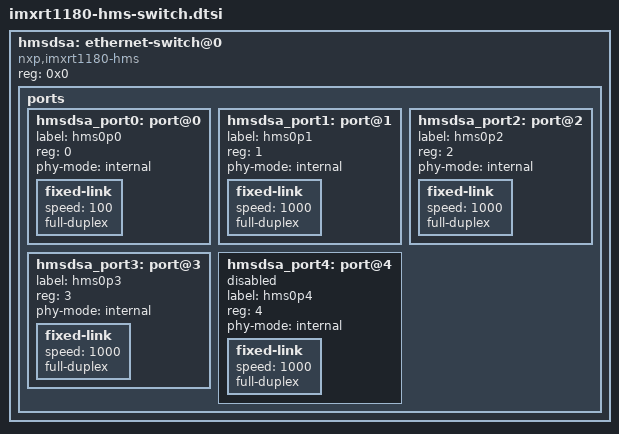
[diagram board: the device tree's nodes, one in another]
// SPDX-License-Identifier: (GPL-2.0+ OR MIT)
/*
 * Copyright 2026 NXP
 */

hmsdsa: ethernet-switch@0 {
	reg = <0x0>;
	#address-cells = <1>;
	#size-cells = <0>;
	compatible = "nxp,imxrt1180-hms";

	ports {
		#address-cells = <1>;
		#size-cells = <0>;

		hmsdsa_port0: port@0 {
			label = "hms0p0";
			reg = <0>;
			phy-mode = "internal";

			fixed-link {
				speed = <100>;
				full-duplex;
			};
		};

		hmsdsa_port1: port@1 {
			label = "hms0p1";
			reg = <1>;
			phy-mode = "internal";

			fixed-link {
				speed = <1000>;
				full-duplex;
			};
		};

		hmsdsa_port2: port@2 {
			label = "hms0p2";
			reg = <2>;
			phy-mode = "internal";

			fixed-link {
				speed = <1000>;
				full-duplex;
			};
		};

		hmsdsa_port3: port@3 {
			label = "hms0p3";
			reg = <3>;
			phy-mode = "internal";

			fixed-link {
				speed = <1000>;
				full-duplex;
			};
		};

		hmsdsa_port4: port@4 {
			label = "hms0p4";
			reg = <4>;
			phy-mode = "internal";
			status = "disabled";

			fixed-link {
				speed = <1000>;
				full-duplex;
			};
		};
	};
};
